# ing916 register map
Vendor: INGChips; Series: ing916xx; File version: 522
CPU: CM4 r0p1, little endian, MPU, FPU, VTOR, 5 interrupt priority bits
Registers are 32-bit, read-write, reset 0x0 unless marked. A register's access mark holds for its fields unless they carry their own. Offsets are from the block's base; [hi:lo] are bit positions; {n}, {i} and the like mark numbered series.

## TRNG
Base 0x40007000
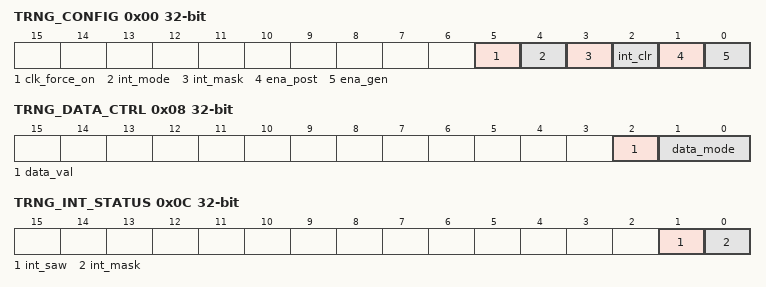
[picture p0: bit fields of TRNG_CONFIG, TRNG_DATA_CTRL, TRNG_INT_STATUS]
0x00 TRNG_CONFIG — reg description:
  [5] clk_force_on — reg description:
  [4] int_mode — reg description:
  [3] int_mask — reg description:
  [2] int_clr — reg description:
  [1] ena_post — reg description:
  [0] ena_gen — reg description:
0x04 TRNG_BIT_SEL — reg description:
  [18:0] bit_sel
0x08 TRNG_DATA_CTRL — reg description:
  [2] data_val — reg description:
  [1:0] data_mode — reg description:
0x0C TRNG_INT_STATUS — reg description:
  [1] int_saw — reg description:
  [0] int_mask — reg description:
0x10 TRNG_DATA — reg description:

## IR
Base 0x4000B000
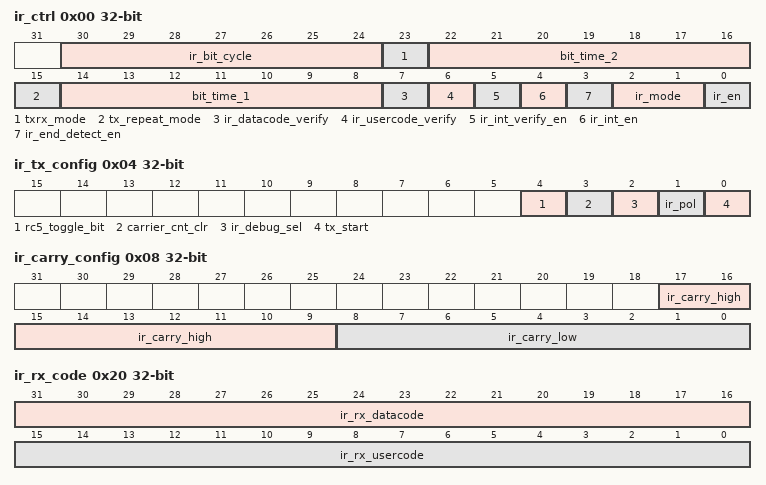
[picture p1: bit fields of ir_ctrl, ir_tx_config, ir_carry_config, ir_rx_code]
0x00 ir_ctrl — reg description:
  [30:24] ir_bit_cycle — reg description:
  [23] txrx_mode — reg description:
  [22:16] bit_time_2 — reg description:
  [15] tx_repeat_mode — reg description:
  [14:8] bit_time_1 — reg description:
  [7] ir_datacode_verify — reg description:
  [6] ir_usercode_verify — reg description:
  [5] ir_int_verify_en — reg description:
  [4] ir_int_en — reg description:
  [3] ir_end_detect_en — reg description:
  [2:1] ir_mode — reg description:
  [0] ir_en — reg description:
0x04 ir_tx_config — reg description:
  [4] rc5_toggle_bit — reg description:
  [3] carrier_cnt_clr — reg description:
  [2] ir_debug_sel — reg description:
  [1] ir_pol — reg description:
  [0] tx_start — reg description:
0x08 ir_carry_config — reg description:
  [17:9] ir_carry_high — reg description:
  [8:0] ir_carry_low — reg description:
{0x8+4i} ir_time_{i} (i=1..5) — reg description:
  [11:0] ir_time_s{i}
0x20 ir_rx_code — reg description:
  [31:16] ir_rx_datacode — reg description:
  [15:0] ir_rx_usercode — reg description:
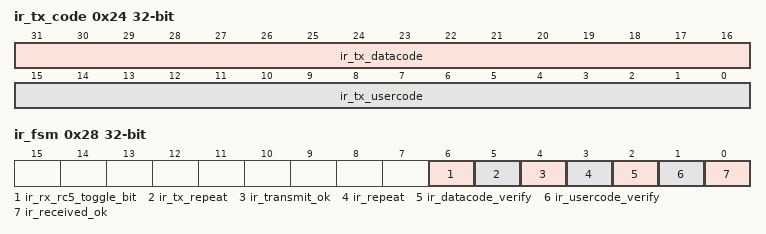
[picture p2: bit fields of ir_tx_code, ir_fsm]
0x24 ir_tx_code — reg description:
  [31:16] ir_tx_datacode — reg description:
  [15:0] ir_tx_usercode — reg description:
0x28 ir_fsm — reg description:
  [6] ir_rx_rc5_toggle_bit — reg description:
  [5] ir_tx_repeat — reg description:
  [4] ir_transmit_ok — reg description:
  [3] ir_repeat — reg description:
  [2] ir_datacode_verify — reg description:
  [1] ir_usercode_verify — reg description:
  [0] ir_received_ok — reg description:

## DMA
Base 0x4000C000
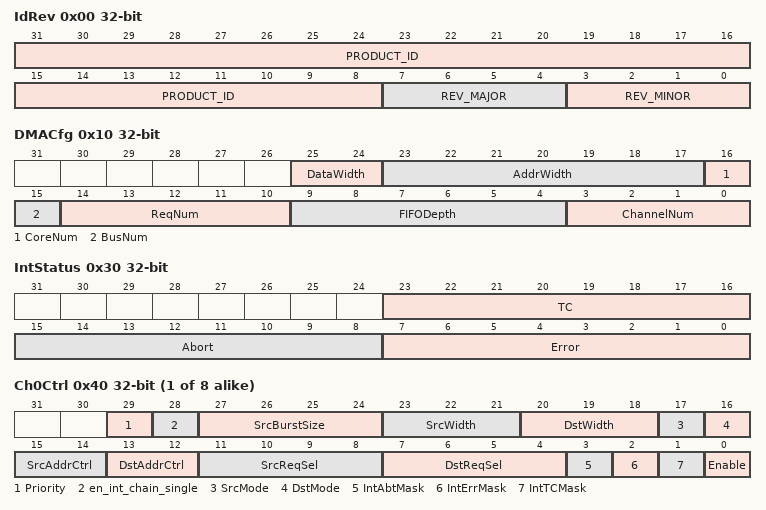
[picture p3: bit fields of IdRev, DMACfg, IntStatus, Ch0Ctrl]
0x00 IdRev — reg description:
  [31:8] PRODUCT_ID — reg description:
  [7:4] REV_MAJOR — reg description:
  [3:0] REV_MINOR — reg description:
0x04 IdMisc — reg description:
0x10 DMACfg — reg description:
  [25:24] DataWidth — reg description:
  [23:17] AddrWidth — reg description:
  [16] CoreNum — reg description:
  [15] BusNum — reg description:
  [14:10] ReqNum — reg description:
  [9:4] FIFODepth — reg description:
  [3:0] ChannelNum — reg description:
0x20 DMACtrl — reg description:
  [0] Reset
0x24 ChAbort — reg description:
  [7:0] ChAbort
0x30 IntStatus — reg description:
  [23:16] TC — reg description:
  [15:8] Abort — reg description:
  [7:0] Error — reg description:
0x34 ChEN — reg description:
  [7:0] ChEN
{0x40+0x20*i} Ch{i}Ctrl (i=0..7) — reg description:
  [29] Priority — reg description:
  [28] en_int_chain_single — reg description:
  [27:24] SrcBurstSize — reg description:
  [23:21] SrcWidth — reg description:
  [20:18] DstWidth — reg description:
  [17] SrcMode — reg description:
  [16] DstMode — reg description:
  [15:14] SrcAddrCtrl — reg description:
  [13:12] DstAddrCtrl — reg description:
  [11:8] SrcReqSel — reg description:
  [7:4] DstReqSel — reg description:
  [3] IntAbtMask — reg description:
  [2] IntErrMask — reg description:
  [1] IntTCMask — reg description:
  [0] Enable — reg description:
{0x44+0x20*i} Ch{i}TranSize (i=0..7) — reg description:
  [31:0] TranSize
{0x48+0x20*i} Ch{i}SrcAddr (i=0..7) — reg description:
  [31:0] SrcAddr
{0x50+0x20*i} Ch{i}DstAddr (i=0..7) — reg description:
  [31:0] DstAddr
{0x58+0x20*i} Ch{i}LLPointer (i=0..7) — reg description:

## Notices in the file
Copyright (c) 2022, INGChips All rights reserved.
Redistribution and use in source and binary forms, with or without
modification, are permitted provided that the following conditions are met:
1. Redistributions of source code must retain the above copyright notice, this
list of conditions and the following disclaimer.
2. Redistributions in binary form must reproduce the above copyright
notice, this list of conditions and the following disclaimer in the
documentation and/or other materials provided with the distribution.
3. Neither the name of Nordic Semiconductor ASA nor the names of its
contributors may be used to endorse or promote products derived from this
software without specific prior written permission.
THIS SOFTWARE IS PROVIDED BY THE COPYRIGHT HOLDERS AND CONTRIBUTORS "AS IS"
AND ANY EXPRESS OR IMPLIED WARRANTIES, INCLUDING, BUT NOT LIMITED TO, THE
IMPLIED WARRANTIES OF MERCHANTABILITY, AND FITNESS FOR A PARTICULAR PURPOSE
ARE DISCLAIMED. IN NO EVENT SHALL NORDIC SEMICONDUCTOR ASA OR CONTRIBUTORS BE
LIABLE FOR ANY DIRECT, INDIRECT, INCIDENTAL, SPECIAL, EXEMPLARY, OR
CONSEQUENTIAL DAMAGES (INCLUDING, BUT NOT LIMITED TO, PROCUREMENT OF
SUBSTITUTE GOODS OR SERVICES; LOSS OF USE, DATA, OR PROFITS; OR BUSINESS
INTERRUPTION) HOWEVER CAUSED AND ON ANY THEORY OF LIABILITY, WHETHER IN
CONTRACT, STRICT LIABILITY, OR TORT (INCLUDING NEGLIGENCE OR OTHERWISE)
ARISING IN ANY WAY OUT OF THE USE OF THIS SOFTWARE, EVEN IF ADVISED OF THE
POSSIBILITY OF SUCH DAMAGE.
